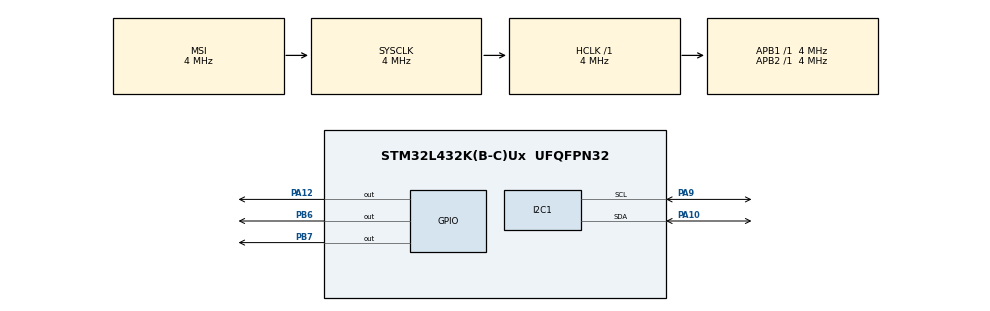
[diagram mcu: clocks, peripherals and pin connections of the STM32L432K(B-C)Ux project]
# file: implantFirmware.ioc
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Mcu.Family=STM32L4
RCC.MSI_VALUE=4000000
RCC.PLLSourceVirtual=RCC_PLLSOURCE_HSI
PA14\ (JTCK-SWCLK).Mode=Serial_Wire
RCC.CortexFreq_Value=4000000
PA10.Mode=I2C
NVIC.RTC_WKUP_IRQn=true\:0\:0\:false\:false\:true\:true\:true
VP_RTC_VS_RTC_Activate.Mode=RTC_Enabled
ProjectManager.StackSize=0x400
PA14\ (JTCK-SWCLK).Signal=SYS_JTCK-SWCLK
PA9.Mode=I2C
PA12.Signal=GPIO_Output
ProjectManager.TargetToolchain=STM32CubeIDE
RCC.HCLKFreq_Value=4000000
RCC.APB2TimFreq_Value=4000000
PA9.Signal=I2C1_SCL
PB6.Signal=GPIO_Output
RCC.USBFreq_Value=64000000
RCC.LSE_VALUE=32768
RCC.AHBFreq_Value=4000000
RCC.HSE_VALUE=8000000
board=custom
RCC.VCOOutputFreq_Value=128000000
RCC.APB2Freq_Value=4000000
RCC.ADCFreq_Value=64000000
PB7.Signal=GPIO_Output
Mcu.Name=STM32L432K(B-C)Ux
PA13\ (JTMS-SWDIO).Mode=Serial_Wire
RCC.SYSCLKFreq_VALUE=4000000
Mcu.Package=UFQFPN32
PA10.Signal=I2C1_SDA
VP_RTC_VS_RTC_Calendar.Mode=RTC_Calendar
ProjectManager.HeapSize=0x200
RCC.HSI_VALUE=16000000
VP_RTC_VS_RTC_WakeUp_intern.Mode=WakeUp
NVIC.PriorityGroup=NVIC_PRIORITYGROUP_1
RCC.APB1TimFreq_Value=4000000
PA13\ (JTMS-SWDIO).Signal=SYS_JTMS-SWDIO
RCC.APB1Freq_Value=4000000
NVIC.RCC_IRQn=true\:1\:0\:true\:false\:true\:true\:false
RCC.HSI48_VALUE=48000000

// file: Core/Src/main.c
/* USER CODE BEGIN Header */
/**
  ******************************************************************************
  * @file           : main.c
  * @brief          : Main program body
  ******************************************************************************
  * @attention
  *
  * <h2><center>&copy; Copyright (c) 2021 STMicroelectronics.
  * All rights reserved.</center></h2>
  *
  * This software component is licensed by ST under BSD 3-Clause license,
  * the "License"; You may not use this file except in compliance with the
  * License. You may obtain a copy of the License at:
  *                        opensource.org/licenses/BSD-3-Clause
  *
  ******************************************************************************
  */
/* USER CODE END Header */
#include "main.h"

I2C_HandleTypeDef hi2c1;

RTC_HandleTypeDef hrtc;

void SystemClock_Config(void);
static void MX_GPIO_Init(void);
static void MX_RTC_Init(void);
static void MX_I2C1_Init(void);

int main(void)
{
  /* USER CODE BEGIN 1 */
	HAL_StatusTypeDef ret;
  /* USER CODE END 1 */

  /* MCU Configuration--------------------------------------------------------*/

  /* Reset of all peripherals, Initializes the Flash interface and the Systick. */
  HAL_Init();

  /* USER CODE BEGIN Init */
  uint16_t raw;
  /* USER CODE END Init */

  /* Configure the system clock */
  SystemClock_Config();

  /* Initialize all configured peripherals */
  MX_GPIO_Init();
  MX_RTC_Init();
  MX_I2C1_Init();
  /* USER CODE BEGIN 2 */

  static const uint16_t REG_DATA = 0x2;
  uint8_t data = 0x3;

  //NFC_WriteToUserAddress(&ret, hi2c1, REG_DATA, data);
  //HAL_Delay(100);

  for(int i = 0; i<30; i++){
	  HAL_GPIO_TogglePin(GPIOB, GPIO_PIN_6);
	  HAL_GPIO_TogglePin(GPIOB, GPIO_PIN_7);
	  HAL_Delay(100);
  }

//	  HAL_Delay(100);
 // }
  //HAL_GPIO_TogglePin(GPIOA, GPIO_PIN_12);

  /* USER CODE END 2 */

  /* Infinite loop */
  while (1)
  {

    /* USER CODE BEGIN 3 */
	// HAL_GPIO_TogglePin(GPIOA, GPIO_PIN_12);
	// stm32l_lowPowerSetup(1000, &hrtc);
	//  HAL_Delay(2000);
	  //HAL_ADC_Start(&hadc1);
	  //HAL_ADC_PollForConversion(&hadc1, HAL_MAX_DELAY);
	  //raw = HAL_ADC_GetValue(&hadc1);
	  NFC_EnableEH(&ret, hi2c1);
	  HAL_GPIO_TogglePin(GPIOB, GPIO_PIN_6);
	  HAL_GPIO_TogglePin(GPIOB, GPIO_PIN_7);
	  HAL_Delay(300);
  }
  /* USER CODE END 3 */
}

void SystemClock_Config(void)
{
  RCC_OscInitTypeDef RCC_OscInitStruct = {0};
  RCC_ClkInitTypeDef RCC_ClkInitStruct = {0};
  RCC_PeriphCLKInitTypeDef PeriphClkInit = {0};

  /** Initializes the RCC Oscillators according to the specified parameters
  * in the RCC_OscInitTypeDef structure.
  */
  RCC_OscInitStruct.OscillatorType = RCC_OSCILLATORTYPE_LSI|RCC_OSCILLATORTYPE_MSI;
  RCC_OscInitStruct.LSIState = RCC_LSI_ON;
  RCC_OscInitStruct.MSIState = RCC_MSI_ON;
  RCC_OscInitStruct.MSICalibrationValue = 0;
  RCC_OscInitStruct.MSIClockRange = RCC_MSIRANGE_6;
  RCC_OscInitStruct.PLL.PLLState = RCC_PLL_NONE;
  if (HAL_RCC_OscConfig(&RCC_OscInitStruct) != HAL_OK)
  {
    Error_Handler();
  }
  /** Initializes the CPU, AHB and APB buses clocks
  */
  RCC_ClkInitStruct.ClockType = RCC_CLOCKTYPE_HCLK|RCC_CLOCKTYPE_SYSCLK
                              |RCC_CLOCKTYPE_PCLK1|RCC_CLOCKTYPE_PCLK2;
  RCC_ClkInitStruct.SYSCLKSource = RCC_SYSCLKSOURCE_MSI;
  RCC_ClkInitStruct.AHBCLKDivider = RCC_SYSCLK_DIV1;
  RCC_ClkInitStruct.APB1CLKDivider = RCC_HCLK_DIV1;
  RCC_ClkInitStruct.APB2CLKDivider = RCC_HCLK_DIV1;

  if (HAL_RCC_ClockConfig(&RCC_ClkInitStruct, FLASH_LATENCY_0) != HAL_OK)
  {
    Error_Handler();
  }
  PeriphClkInit.PeriphClockSelection = RCC_PERIPHCLK_RTC|RCC_PERIPHCLK_I2C1;
  PeriphClkInit.I2c1ClockSelection = RCC_I2C1CLKSOURCE_PCLK1;
  PeriphClkInit.RTCClockSelection = RCC_RTCCLKSOURCE_LSI;
  if (HAL_RCCEx_PeriphCLKConfig(&PeriphClkInit) != HAL_OK)
  {
    Error_Handler();
  }
  /** Configure the main internal regulator output voltage
  */
  if (HAL_PWREx_ControlVoltageScaling(PWR_REGULATOR_VOLTAGE_SCALE1) != HAL_OK)
  {
    Error_Handler();
  }
}

static void MX_I2C1_Init(void)
{

  hi2c1.Instance = I2C1;
  hi2c1.Init.Timing = 0x00000E14;
  hi2c1.Init.OwnAddress1 = 0;
  hi2c1.Init.AddressingMode = I2C_ADDRESSINGMODE_7BIT;
  hi2c1.Init.DualAddressMode = I2C_DUALADDRESS_DISABLE;
  hi2c1.Init.OwnAddress2 = 0;
  hi2c1.Init.OwnAddress2Masks = I2C_OA2_NOMASK;
  hi2c1.Init.GeneralCallMode = I2C_GENERALCALL_DISABLE;
  hi2c1.Init.NoStretchMode = I2C_NOSTRETCH_DISABLE;
  if (HAL_I2C_Init(&hi2c1) != HAL_OK)
  {
    Error_Handler();
  }
  /** Configure Analogue filter
  */
  if (HAL_I2CEx_ConfigAnalogFilter(&hi2c1, I2C_ANALOGFILTER_ENABLE) != HAL_OK)
  {
    Error_Handler();
  }
  /** Configure Digital filter
  */
  if (HAL_I2CEx_ConfigDigitalFilter(&hi2c1, 0) != HAL_OK)
  {
    Error_Handler();
  }

}

static void MX_RTC_Init(void)
{

  RTC_TimeTypeDef sTime = {0};
  RTC_DateTypeDef sDate = {0};

  /** Initialize RTC Only
  */
  hrtc.Instance = RTC;
  hrtc.Init.HourFormat = RTC_HOURFORMAT_24;
  hrtc.Init.AsynchPrediv = 127;
  hrtc.Init.SynchPrediv = 255;
  hrtc.Init.OutPut = RTC_OUTPUT_DISABLE;
  hrtc.Init.OutPutRemap = RTC_OUTPUT_REMAP_NONE;
  hrtc.Init.OutPutPolarity = RTC_OUTPUT_POLARITY_HIGH;
  hrtc.Init.OutPutType = RTC_OUTPUT_TYPE_OPENDRAIN;
  if (HAL_RTC_Init(&hrtc) != HAL_OK)
  {
    Error_Handler();
  }

  /** Initialize RTC and set the Time and Date
  */
  sTime.Hours = 0x0;
  sTime.Minutes = 0x0;
  sTime.Seconds = 0x0;
  sTime.DayLightSaving = RTC_DAYLIGHTSAVING_NONE;
  sTime.StoreOperation = RTC_STOREOPERATION_RESET;
  if (HAL_RTC_SetTime(&hrtc, &sTime, RTC_FORMAT_BCD) != HAL_OK)
  {
    Error_Handler();
  }
  sDate.WeekDay = RTC_WEEKDAY_MONDAY;
  sDate.Month = RTC_MONTH_JANUARY;
  sDate.Date = 0x1;
  sDate.Year = 0x0;

  if (HAL_RTC_SetDate(&hrtc, &sDate, RTC_FORMAT_BCD) != HAL_OK)
  {
    Error_Handler();
  }
  /** Enable the WakeUp
  */
  if (HAL_RTCEx_SetWakeUpTimer_IT(&hrtc, 0, RTC_WAKEUPCLOCK_RTCCLK_DIV16) != HAL_OK)
  {
    Error_Handler();
  }

}

static void MX_GPIO_Init(void)
{
  GPIO_InitTypeDef GPIO_InitStruct = {0};

  /* GPIO Ports Clock Enable */
  __HAL_RCC_GPIOA_CLK_ENABLE();
  __HAL_RCC_GPIOB_CLK_ENABLE();

  /*Configure GPIO pin Output Level */
  HAL_GPIO_WritePin(GPIOA, GPIO_PIN_12, GPIO_PIN_RESET);

  /*Configure GPIO pin Output Level */
  HAL_GPIO_WritePin(GPIOB, GPIO_PIN_6|GPIO_PIN_7, GPIO_PIN_RESET);

  /*Configure GPIO pin : PA12 */
  GPIO_InitStruct.Pin = GPIO_PIN_12;
  GPIO_InitStruct.Mode = GPIO_MODE_OUTPUT_PP;
  GPIO_InitStruct.Pull = GPIO_NOPULL;
  GPIO_InitStruct.Speed = GPIO_SPEED_FREQ_LOW;
  HAL_GPIO_Init(GPIOA, &GPIO_InitStruct);

  /*Configure GPIO pins : PB6 PB7 */
  GPIO_InitStruct.Pin = GPIO_PIN_6|GPIO_PIN_7;
  GPIO_InitStruct.Mode = GPIO_MODE_OUTPUT_PP;
  GPIO_InitStruct.Pull = GPIO_NOPULL;
  GPIO_InitStruct.Speed = GPIO_SPEED_FREQ_LOW;
  HAL_GPIO_Init(GPIOB, &GPIO_InitStruct);

}

void Error_Handler(void)
{
  __disable_irq();
  while (1)
  {
  }
}

/************************ (C) COPYRIGHT STMicroelectronics *****END OF FILE****/
